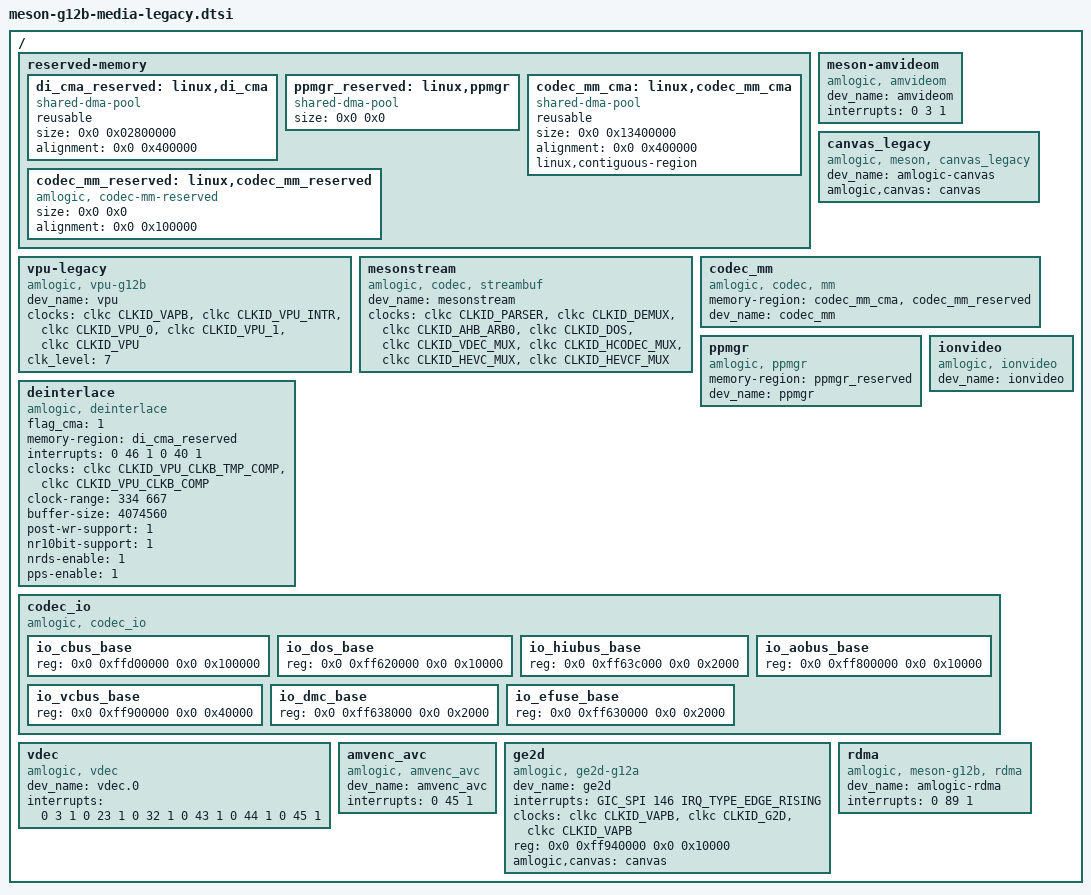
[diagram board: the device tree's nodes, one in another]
// SPDX-License-Identifier: (GPL-2.0+ OR MIT)
/*
 * Copyright (c) 2019 BayLibre, SAS
 * Author: Neil Armstrong <narmstrong@baylibre.com>
 */

#include <dt-bindings/clock/g12a-clkc.h>

/ {

	reserved-memory {
		#address-cells = <2>;
		#size-cells = <2>;
		ranges;

		/*di CMA pool */
		di_cma_reserved:linux,di_cma {
			compatible = "shared-dma-pool";
			reusable;
			/* buffer_size = 3621952(yuv422 8bit)
			 *  | 4736064(yuv422 10bit)
			 *  | 4074560(yuv422 10bit full pack mode)
			 * 10x3621952=34.6M(0x23) support 8bit
			 * 10x4736064=45.2M(0x2e) support 12bit
			 * 10x4074560=40M(0x28) support 10bit
			 */
			size = <0x0 0x02800000>;
			alignment = <0x0 0x400000>;
		};

		/*  POST PROCESS MANAGER */
		ppmgr_reserved:linux,ppmgr {
			compatible = "shared-dma-pool";
			size = <0x0 0x0>;
		};
		
		codec_mm_cma:linux,codec_mm_cma {
			compatible = "shared-dma-pool";
			reusable;
			/* ion_codec_mm max can alloc size 80M*/
			size = <0x0 0x13400000>;
			alignment = <0x0 0x400000>;
			linux,contiguous-region;
		};

		/* codec shared reserved */
		codec_mm_reserved:linux,codec_mm_reserved {
			compatible = "amlogic, codec-mm-reserved";
			size = <0x0 0x0>;
			alignment = <0x0 0x100000>;
			//no-map;
		};
	};
		
	vpu-legacy {
		compatible = "amlogic, vpu-g12b";
		dev_name = "vpu";
		status = "okay";
		clocks = <&clkc CLKID_VAPB>,
			<&clkc CLKID_VPU_INTR>,
			<&clkc CLKID_VPU_0>,
			<&clkc CLKID_VPU_1>,
			<&clkc CLKID_VPU>;
		clock-names = "vapb_clk",
			"vpu_intr_gate",
			"vpu_clk0",
			"vpu_clk1",
			"vpu_clk";
		clk_level = <7>;
		/* 0: 100.0M    1: 166.7M    2: 200.0M    3: 250.0M */
		/* 4: 333.3M    5: 400.0M    6: 500.0M    7: 666.7M */
	};

	meson-amvideom {
		compatible = "amlogic, amvideom";
		dev_name = "amvideom";
		status = "okay";
		interrupts = <0 3 1>;
		interrupt-names = "vsync";
	};

	mesonstream {
		compatible = "amlogic, codec, streambuf";
		dev_name = "mesonstream";
		status = "okay";
		clocks = <&clkc CLKID_PARSER
			&clkc CLKID_DEMUX
			&clkc CLKID_AHB_ARB0
			&clkc CLKID_DOS
			&clkc CLKID_VDEC_MUX
			&clkc CLKID_HCODEC_MUX
			&clkc CLKID_HEVC_MUX
			&clkc CLKID_HEVCF_MUX>;
		clock-names = "parser_top",
			"demux",
			"ahbarb0",
			"vdec",
			"clk_vdec_mux",
			"clk_hcodec_mux",
			"clk_hevc_mux",
			"clk_hevcb_mux";
	};
	
	canvas_legacy: canvas_legacy {
		compatible = "amlogic, meson, canvas_legacy";
		dev_name = "amlogic-canvas";
		status = "okay";
		amlogic,canvas = <&canvas>;
	};
	
	codec_mm {
		compatible = "amlogic, codec, mm";
		memory-region = <&codec_mm_cma &codec_mm_reserved>;
		dev_name = "codec_mm";
		status = "okay";
	};
	
	ppmgr {
		compatible = "amlogic, ppmgr";
		memory-region = <&ppmgr_reserved>;
		dev_name = "ppmgr";
		status = "okay";
	};

	deinterlace {
		compatible = "amlogic, deinterlace";
		status = "okay";
		/* 0:use reserved; 1:use cma; 2:use cma as reserved */
		flag_cma = <1>;
		//memory-region = <&di_reserved>;
		memory-region = <&di_cma_reserved>;
		interrupts = <0 46 1
						0 40 1>;
		interrupt-names = "pre_irq", "post_irq";
		clocks = <&clkc CLKID_VPU_CLKB_TMP_COMP>,
				<&clkc CLKID_VPU_CLKB_COMP>;
		clock-names = "vpu_clkb_tmp_composite",
				"vpu_clkb_composite";
		clock-range = <334 667>;
		/* buffer-size = <3621952>;(yuv422 8bit) */
		buffer-size = <4074560>;/*yuv422 fullpack*/
		/* reserve-iomap = "true"; */
		/* if enable nr10bit, set nr10bit-support to 1 */
		post-wr-support = <1>;
		nr10bit-support = <1>;
		nrds-enable = <1>;
		pps-enable = <1>;
	};

	ionvideo {
		compatible = "amlogic, ionvideo";
		dev_name = "ionvideo";
		status = "okay";
	};
	
	codec_io: codec_io {
		compatible = "amlogic, codec_io";
		status = "okay";
		#address-cells=<2>;
		#size-cells=<2>;
		ranges;
		io_cbus_base{
				reg = <0x0 0xffd00000 0x0 0x100000>;
		};
		io_dos_base{
				reg = <0x0 0xff620000 0x0 0x10000>;
		};
		io_hiubus_base{
				reg = <0x0 0xff63c000 0x0 0x2000>;
		};
		io_aobus_base{
				reg = <0x0 0xff800000 0x0 0x10000>;
		};
		io_vcbus_base{
				reg = <0x0 0xff900000 0x0 0x40000>;
		};
		io_dmc_base{
				reg = <0x0 0xff638000 0x0 0x2000>;
		};
		io_efuse_base{
				reg = <0x0 0xff630000 0x0 0x2000>;
		};
	};

	vdec {
		compatible = "amlogic, vdec";
		dev_name = "vdec.0";
		status = "okay";
		interrupts = <0 3 1
				0 23 1
				0 32 1
				0 43 1
				0 44 1
				0 45 1>;
		interrupt-names = "vsync",
				"demux",
				"parser",
				"mailbox_0",
				"mailbox_1",
				"mailbox_2";
	};

	amvenc_avc {
		compatible = "amlogic, amvenc_avc";
		dev_name = "amvenc_avc";
		status = "okay";
		interrupts = <0 45 1>;
		interrupt-names = "mailbox_2";
	};
	
	ge2d {
		compatible = "amlogic, ge2d-g12a";
		dev_name = "ge2d";
		status = "okay";
		interrupts = <GIC_SPI 146 IRQ_TYPE_EDGE_RISING>;
		interrupt-names = "ge2d";
		clocks = <&clkc CLKID_VAPB>,
			<&clkc CLKID_G2D>,
			<&clkc CLKID_VAPB>;
		clock-names = "clk_vapb_0",
			"clk_ge2d",
			"clk_ge2d_gate";
		reg = <0x0 0xff940000 0x0 0x10000>;
		amlogic,canvas = <&canvas>;
	};

	rdma {
		compatible = "amlogic, meson-g12b, rdma";
		dev_name = "amlogic-rdma";
		status = "okay";
		interrupts = <0 89 1>;
		interrupt-names = "rdma";
	};
};
